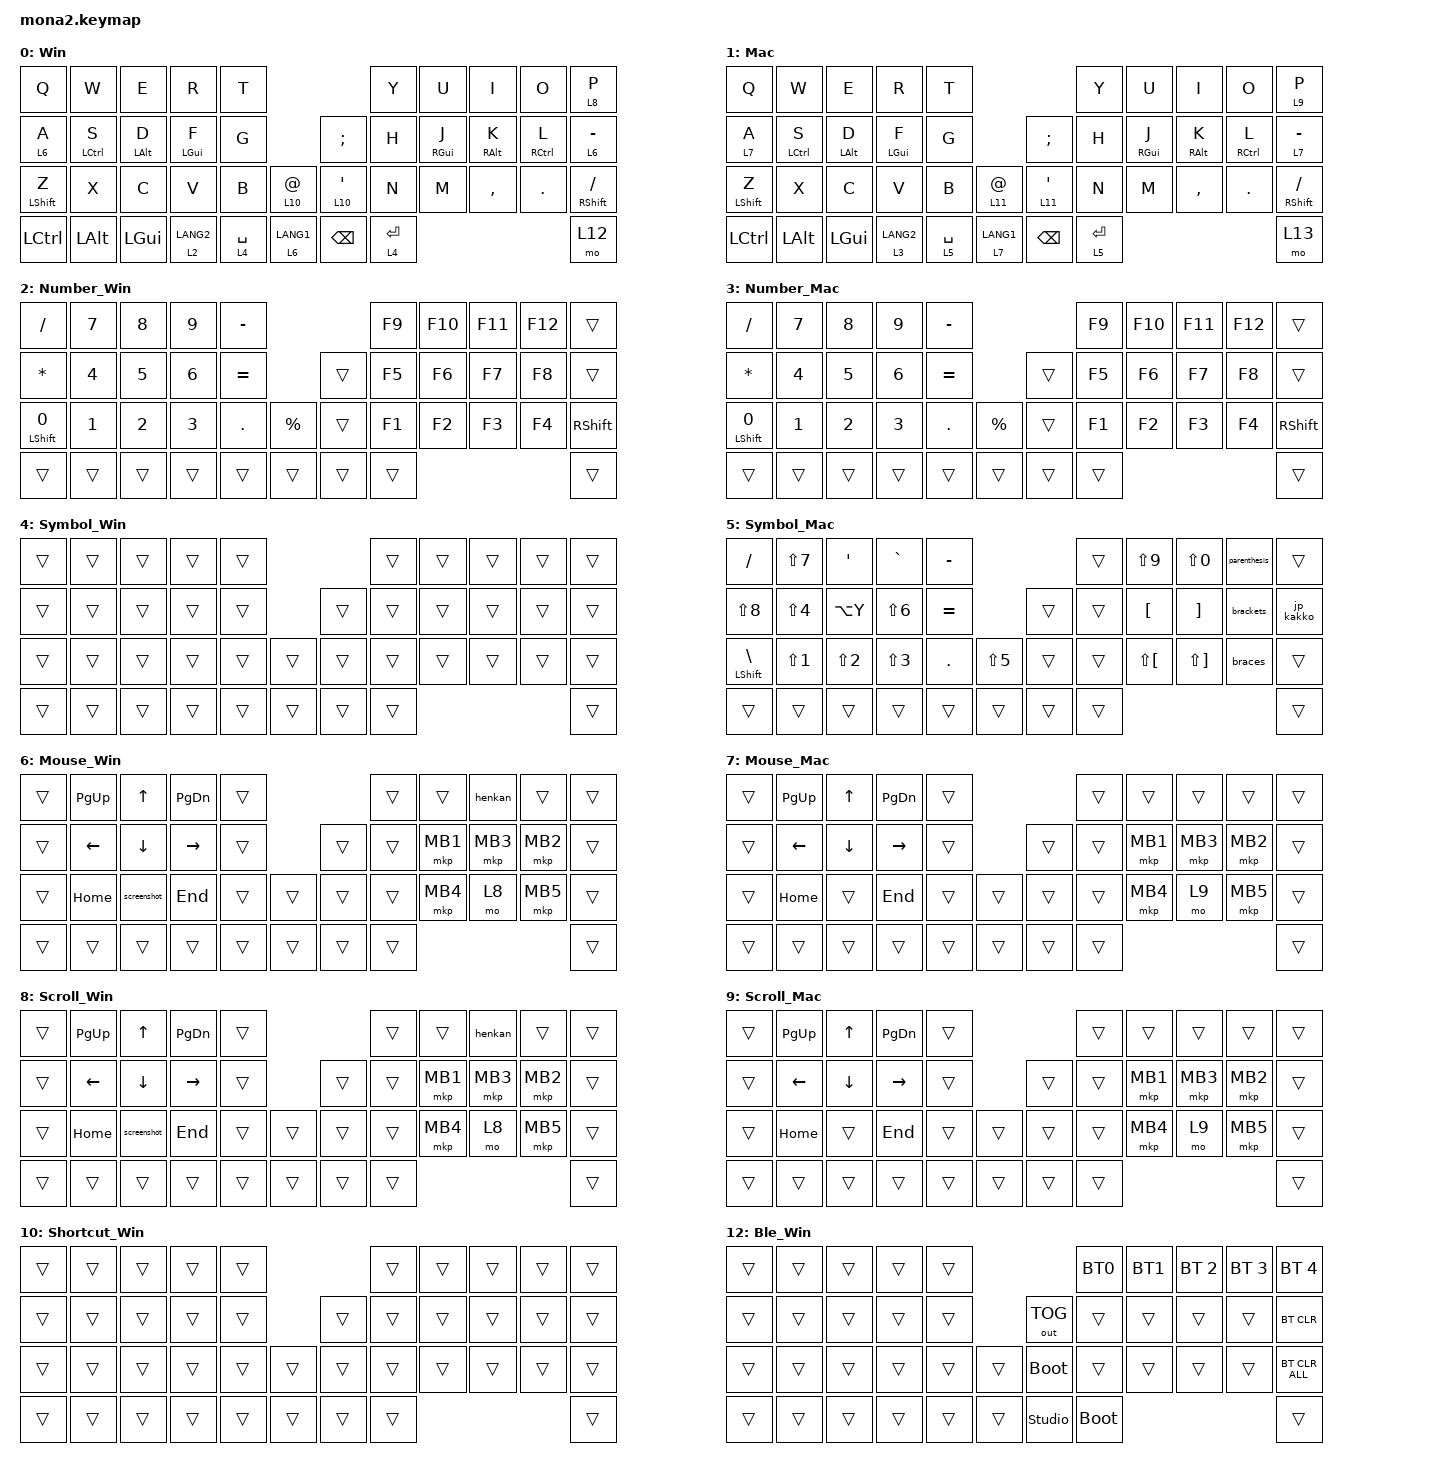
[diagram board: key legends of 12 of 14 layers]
#include <input/processors.dtsi>
#include <dt-bindings/zmk/input_transform.h>
#include <zephyr/dt-bindings/input/input-event-codes.h>
#include <behaviors/runtime-sensor-rotate.dtsi>
#include <behaviors.dtsi>
/* DYA Studio から作成したマクロを呼び出す `&rmacro <slot>` を定義する。
   slot は 0 〜 CONFIG_ZMK_RUNTIME_MACRO_COUNT-1 (現状 0〜7)。
   どのマクロがどのスロットに入っているかは DYA Studio のマクロ一覧で確認する。
   キーへの割り当ては DYA Studio のキーマップエディタからも行える。 */
#include <behaviors/runtime_macro.dtsi>
/* デフォルトレイヤー変更 behavior `&df`。
   DYA Studio の「OSごとのデフォルトレイヤー」から設定できるほか、
   キーマップエディタで `&df DF_SEL <layer>` / `&df DF_INC` を
   任意のキーに割り当てられる。 */
#include <behaviors/default_layer.dtsi>
#include <dt-bindings/zmk_behavior_default_layer/default_layer.h>
#include <dt-bindings/zmk/bt.h>
#include <dt-bindings/zmk/keys.h>
#include <dt-bindings/zmk/outputs.h>
#include <dt-bindings/zmk/pointing.h>
/* ZMK Layout Shift Module */
#include <layout_shift_kp_override.dtsi>

/* ZMK 側で 10 が定義済みなので警告回避のため一旦 undef */

#undef ZMK_POINTING_DEFAULT_SCRL_VAL

#define ZMK_POINTING_DEFAULT_SCRL_VAL 100

/ {
    behaviors {
        mg_set_0: behavior_mg_set_0 {
            compatible = "zmk,behavior-mg-set-fixed";
            #binding-cells = <0>;
            display-name = "Mouse Gesture Key 0";
        };

        mg_set_1: behavior_mg_set_1 {
            compatible = "zmk,behavior-mg-set-fixed";
            #binding-cells = <0>;
            display-name = "Mouse Gesture Key 1";
        };

        mg_set_2: behavior_mg_set_2 {
            compatible = "zmk,behavior-mg-set-fixed";
            #binding-cells = <0>;
            display-name = "Mouse Gesture Key 2";
        };
    };
};

&mt {
    flavor = "balanced";
    quick-tap-ms = <200>;
    require-prior-idle-ms = <150>;
};

&lt {
    quick-tap-ms = <200>;
    /*
    flavor = "tap-preferred";
    tapping-term-ms = <300>;
    */
    flavor = "balanced";
    require-prior-idle-ms = <150>;
};

&msc {
    delay-ms = <0>;
    time-to-max-speed-ms = <0>;
    acceleration-exponent = <0>;
};

&tog_ls { layout-maps = <&layout_shift_map_us_to_jis &layout_shift_map_swap_ctrl_cmd>; };
&tog_ls_on { layout-maps = <&layout_shift_map_us_to_jis &layout_shift_map_swap_ctrl_cmd>; };
&tog_ls_off { layout-maps = <&layout_shift_map_us_to_jis &layout_shift_map_swap_ctrl_cmd>; };

/ {
    /* ─────────────────────────────────────────────────────────────
       コンボ (DYA Studio から編集可能)

       旧 `combos { compatible = "zmk,combos"; }` はコンパイル時固定で
       DYA Studio から編集できないため、zmk-feature-runtime-combo の
       「コンパイル時デフォルト」ノードへ移行した。
       ここに書いた内容はフラッシュ直後から有効で、設定を消しても復活する。
       DYA Studio 側で編集するとそのスロットだけ上書きされ、
       Web UI の "Reset to Default" でここの値へ戻せる。

       スロット総数は CONFIG_ZMK_RUNTIME_COMBO_MAX_COMBOS (現状 16)。
       未使用スロット (2〜15) は DYA Studio から自由に追加できる。
       ────────────────────────────────────────────────────────── */
    runtime_combo_defaults {
        compatible = "cormoran,runtime-combo-defaults";

        esc {
            slot = <0>;
            display-name = "Esc";
            key-positions = <38 39>;
            bindings = <&kp ESC>;
        };

        tab {
            slot = <1>;
            display-name = "Tab";
            key-positions = <11 12>;
            bindings = <&kp TAB>;
        };

        toggle_us_jis {
            slot = <2>;
            display-name = "Toggle US<->JIS";
            key-positions = <4 5>;
            bindings = <&tog_ls>;
        };
    };

    /* 静的マクロ。キーマップ上で &BT0 / &screenshot などの名前で直接
       参照しているため、そのまま残している (DYA Studio 上では編集不可)。
       DYA Studio から編集したいマクロは Web UI で新規作成し、
       キーに `&rmacro <slot>` を割り当てて使う。 */
    macros {
        to_layer_0: to_layer_0 {
            compatible = "zmk,behavior-macro-one-param";
            #binding-cells = <1>;
            bindings = <&to 0 &macro_param_1to1 &kp MACRO_PLACEHOLDER>;
            label = "TO_LAYER_0";
        };

        BT0: BT0 {
            compatible = "zmk,behavior-macro";
            #binding-cells = <0>;
            bindings =
                <&tog_off 0 &tog_off 1>,
                <&macro_wait_time 200>,
                <&bt BT_SEL 0>,
                <&macro_wait_time 500>,
                <&tog_on 0>;

            label = "BT0";
        };

        BT1: BT1 {
            compatible = "zmk,behavior-macro";
            #binding-cells = <0>;
            bindings =
                <&tog_off 0 &tog_off 1>,
                <&macro_wait_time 200>,
                <&bt BT_SEL 1>,
                <&macro_wait_time 500>,
                <&tog_on 1>;

            label = "BT1";
        };

        screenshot: screenshot {
            compatible = "zmk,behavior-macro";
            #binding-cells = <0>;
            bindings =
                <&macro_press>,
                <&kp LEFT_GUI &kp RSHIFT>,
                <&macro_wait_time 20>,
                <&macro_tap>,
                <&kp S>,
                <&macro_release>,
                <&kp LEFT_GUI &kp RSHIFT>;

            label = "SCREENSHOT";
        };

        henkan: henkan {
            compatible = "zmk,behavior-macro";
            #binding-cells = <0>;
            bindings =
                <&macro_press>,
                <&kp LEFT_ALT>,
                <&macro_wait_time 20>,
                <&macro_tap>,
                <&kp GRAVE>,
                <&macro_release>,
                <&kp LEFT_ALT>;

            label = "HENKAN";
        };

        parenthesis: parenthesis {
            compatible = "zmk,behavior-macro";
            #binding-cells = <0>;
            bindings = 
                <&kp LANG2>,
                <&macro_wait_time 50>,
                <&kp LEFT_PARENTHESIS>,
                <&kp RIGHT_PARENTHESIS>,
                <&kp LEFT>;
        };

        brackets: brackets {
            compatible = "zmk,behavior-macro";
            #binding-cells = <0>;
            bindings = 
                <&kp LANG2>,
                <&macro_wait_time 50>,
                <&kp LEFT_BRACKET>,
                <&kp RIGHT_BRACKET>,
                <&kp LEFT>;
        };

        braces: braces {
            compatible = "zmk,behavior-macro";
            #binding-cells = <0>;
            bindings = 
                <&kp LANG2>,
                <&macro_wait_time 50>,
                <&kp LEFT_BRACE>,
                <&kp RIGHT_BRACE>,
                <&kp LEFT>;
        };

        jp_kakko: jp_kakko {
            compatible = "zmk,behavior-macro";
            #binding-cells = <0>;
            bindings = 
                <&kp LANG1>,
                <&macro_wait_time 50>,
                <&kp LEFT_BRACKET>,
                <&kp RIGHT_BRACKET>,
                <&kp ENTER>,
                <&kp LEFT>;
        };
    };

    behaviors {
        lt_to_layer_0: lt_to_layer_0 {
            compatible = "zmk,behavior-hold-tap";
            label = "LAYER_TAP_TO_0";
            bindings = <&mo>, <&to_layer_0>;

            #binding-cells = <2>;
            tapping-term-ms = <200>;
        };

        tp_repeat_mo1: tp_repeat_mo1 {
            compatible = "zmk,behavior-hold-tap";
            label = "TP_REPEAT_MO1";
            bindings = <&mo>, <&key_repeat>;

            #binding-cells = <2>;
            tapping-term-ms = <200>;
        };

        // エンコーダ用 runtime-configurable sensor rotate
        // デフォルトはスクロール (cw=SCRL_DOWN, ccw=SCRL_UP)
        // DYA Studio Web UI から レイヤーごとに cw/ccw の binding を
        // kp C_VOL_UP/DN や kp LEFT/RIGHT などへ動的変更可能

        rsr_scrl_up_down: rsr_scrl_up_down {
            compatible = "zmk,behavior-runtime-sensor-rotate";
            #sensor-binding-cells = <0>;
            tap-ms = <16>;
            cw-binding = <&msc SCRL_DOWN>;
            ccw-binding = <&msc SCRL_UP>;
        };

        rsr_scrl_right_left: rsr_scrl_right_left {
            compatible = "zmk,behavior-runtime-sensor-rotate";
            #sensor-binding-cells = <0>;
            tap-ms = <16>;
            cw-binding = <&msc SCRL_LEFT>;
            ccw-binding = <&msc SCRL_RIGHT>;
        };

        /*
        rsr_mouse_scroll: mouse_wheel_scroll {
            compatible = "zmk,behavior-sensor-rotate-var";
            #sensor-binding-cells = <2>;
            bindings = <&msc>, <&msc>;
            // 追加: スクロールのタップ時間を設定 (20ms)
            tap-ms = <20>;
        };
        */

        tog_on: toggle_layer_on_only {
            compatible = "zmk,behavior-toggle-layer";
            #binding-cells = <1>;
            display-name = "Toggle Layer On";
            toggle-mode = "on";
        };

        tog_off: toggle_layer_off_only {
            compatible = "zmk,behavior-toggle-layer";
            #binding-cells = <1>;
            display-name = "Toggle Layer Off";
            toggle-mode = "off";
        };

        zfold: zfold {
            compatible = "zmk,behavior-hold-tap";
            label = "ZFOLD";
            bindings = <&kp>, <&kp>;

            #binding-cells = <2>;
            tapping-term-ms = <300>;
            flavor = "hold-preferred";
            quick-tap-ms = <150>;
            hold-while-undecided;
        };

        zfoldZ: zfoldZ {
            compatible = "zmk,behavior-tap-dance";
            label = "ZFOLDZ";
            #binding-cells = <0>;
            bindings = <&zfold LEFT_SHIFT Z>, <&kp LS(Z)>;
        };
    };

    /* Defined Keymap Layers
        0   :   Win
        1   :   Mac
        2   :   Number_Win
        3   :   Number_Mac
        4   :   Symbol_Win
        5   :   Symbol_Mac
        6   :   Mouse_Win
        7   :   Mouse_Mac
        8   :   Scroll_Win
        9   :   Scroll_Mac
        10  :   Shortcut_Win
        11  :   Shortcut_Mac
        12  :   Ble_Win
        13  :   Ble_Mac
    */
    /* moNa2 Physical Key Layout
        bindings = <
            K0      K1      K2      K3      K4                          K5      K6      K7      K8      K9
            K10     K11     K12     K13     K14                 K15     K16     K17     K18     K19     K20
            K21     K22     K23     K24     K25     K26         K27     K28     K29     K30     K31     K32
            K33     K34     K35     K36     K37     K38         K39     K40                             K41
        >;
    */
    keymap {
        compatible = "zmk,keymap";

        win_layer {
            display-name = "Win";
            bindings = <
&kp Q             &kp W         &kp E         &kp R        &kp T                                       &kp Y          &kp U      &kp I      &kp O        &lt 8 P
&lt 6 A           &mt LCTRL S   &mt LALT D    &mt LGUI F   &kp G                        &kp SEMICOLON  &kp H          &mt RGUI J &mt RALT K &mt RCTRL L  &lt 6 MINUS
&mt LSHFT Z       &kp X         &kp C         &kp V        &kp B        &lt 10 AT       &lt 10 SQT     &kp N          &kp M      &kp COMMA  &kp DOT      &mt RSHFT SLASH
&kp LCTRL         &kp LALT      &kp LGUI      &lt 2 LANG2  &lt 4 SPACE  &lt 6 LANG1     &kp BSPC       &lt 4 ENTER                                       &mo 12
            >;

            sensor-bindings = <&rsr_scrl_up_down>, <&inc_dec_kp C_VOL_DN C_VOL_UP>;
        };

        mac_layer {
            display-name = "Mac";
            bindings = <
&kp Q             &kp W         &kp E         &kp R        &kp T                                       &kp Y          &kp U      &kp I      &kp O        &lt 9 P
&lt 7 A           &mt LCTRL S   &mt LALT D    &mt LGUI F   &kp G                        &kp SEMICOLON  &kp H          &mt RGUI J &mt RALT K &mt RCTRL L  &lt 7 MINUS
&mt LSHFT Z       &kp X         &kp C         &kp V        &kp B        &lt 11 AT       &lt 11 SQT     &kp N          &kp M      &kp COMMA  &kp DOT      &mt RSHFT SLASH
&kp LCTRL         &kp LALT      &kp LGUI      &lt 3 LANG2  &lt 5 SPACE  &lt 7 LANG1     &kp BSPC       &lt 5 ENTER                                       &mo 13
            >;

            sensor-bindings = <&rsr_scrl_up_down>, <&inc_dec_kp C_VOL_DN C_VOL_UP>;
        };

        num_win {
            display-name = "Number_Win";
            bindings = <
&kp SLASH       &kp N7 &kp N8 &kp N9 &kp MINUS                       &kp F9   &kp F10 &kp F11 &kp F12 &trans
&kp ASTERISK    &kp N4 &kp N5 &kp N6 &kp EQUAL                &trans &kp F5   &kp F6  &kp F7  &kp F8  &trans
&mt LSHFT N0    &kp N1 &kp N2 &kp N3 &kp DOT   &kp PERCENT    &trans &kp F1   &kp F2  &kp F3  &kp F4  &kp RSHFT
&trans          &trans &trans &trans &trans    &trans         &trans &trans                           &trans
            >;

            sensor-bindings = <&rsr_scrl_up_down>;
        };

        num_mac {
            display-name = "Number_Mac";
            bindings = <
&kp SLASH       &kp N7 &kp N8 &kp N9 &kp MINUS                       &kp F9   &kp F10 &kp F11 &kp F12 &trans
&kp ASTERISK    &kp N4 &kp N5 &kp N6 &kp EQUAL                &trans &kp F5   &kp F6  &kp F7  &kp F8  &trans
&mt LSHFT N0    &kp N1 &kp N2 &kp N3 &kp DOT   &kp PERCENT    &trans &kp F1   &kp F2  &kp F3  &kp F4  &kp RSHFT
&trans          &trans &trans &trans &trans    &trans         &trans &trans                           &trans
            >;

            sensor-bindings = <&rsr_scrl_up_down>;
        };

        symbol_win {
            display-name = "Symbol_Win";
            bindings = <
&trans  &trans  &trans  &trans  &trans                    &trans  &trans  &trans  &trans  &trans
&trans  &trans  &trans  &trans  &trans            &trans  &trans  &trans  &trans  &trans  &trans
&trans  &trans  &trans  &trans  &trans  &trans    &trans  &trans  &trans  &trans  &trans  &trans
&trans  &trans  &trans  &trans  &trans  &trans    &trans  &trans                          &trans
            >;

            sensor-bindings = <&rsr_scrl_up_down>;
        };

        symbol_mac {
            display-name = "Symbol_Mac";
            bindings = <
&kp SLASH       &kp LS(N7)  &kp SQT     &kp GRAVE   &kp MINUS                       &trans  &kp LS(N9)      &kp LS(N0)      &parenthesis    &trans
&kp LS(N8)      &kp LS(N4)  &kp LA(Y)   &kp LS(N6)  &kp EQUAL               &trans  &trans  &kp LBKT        &kp RBKT        &brackets       &jp_kakko
&mt LSHFT BSLH  &kp LS(N1)  &kp LS(N2)  &kp LS(N3)  &kp DOT     &kp LS(N5)  &trans  &trans  &kp LS(LBKT)    &kp LS(RBKT)    &braces         &trans
&trans          &trans      &trans      &trans      &trans      &trans      &trans  &trans                                                  &trans
            >;

            sensor-bindings = <&rsr_scrl_up_down>;
        };

        mouse_win {
            display-name = "Mouse_Win";
            bindings = <
&trans  &kp PG_UP       &kp UP          &kp PG_DN        &trans                             &trans      &trans          &henkan         &trans          &trans
&trans  &kp LEFT        &kp DOWN        &kp RIGHT        &trans                 &trans      &trans      &mkp MB1        &mkp MB3        &mkp MB2        &trans
&trans  &kp HOME        &screenshot     &kp END          &trans     &trans      &trans      &trans      &mkp MB4        &mo 8           &mkp MB5        &trans
&trans  &trans          &trans          &trans           &trans     &trans      &trans      &trans                                                      &trans
            >;

            sensor-bindings = <&rsr_scrl_up_down>;
        };

        mouse_mac {
            display-name = "Mouse_Mac";
            bindings = <
&trans  &kp PG_UP   &kp UP    &kp PG_DN     &trans                             &trans      &trans          &trans          &trans          &trans
&trans  &kp LEFT    &kp DOWN  &kp RIGHT     &trans                 &trans      &trans      &mkp MB1        &mkp MB3        &mkp MB2        &trans
&trans  &kp HOME    &trans    &kp END       &trans     &trans      &trans      &trans      &mkp MB4        &mo 9           &mkp MB5        &trans
&trans  &trans      &trans    &trans        &trans     &trans      &trans      &trans                                                      &trans
            >;

            sensor-bindings = <&rsr_scrl_up_down>;
        };

        scroll_win {
            display-name = "Scroll_Win";
            bindings = <
&trans  &kp PG_UP   &kp UP          &kp PG_DN   &trans                             &trans      &trans          &henkan         &trans          &trans
&trans  &kp LEFT    &kp DOWN        &kp RIGHT   &trans                 &trans      &trans      &mkp MB1        &mkp MB3        &mkp MB2        &trans
&trans  &kp HOME    &screenshot     &kp END     &trans     &trans      &trans      &trans      &mkp MB4        &mo 8           &mkp MB5        &trans
&trans  &trans      &trans          &trans      &trans     &trans      &trans      &trans                                                      &trans
            >;

            sensor-bindings = <&rsr_scrl_right_left>;
        };

        scroll_mac {
            display-name = "Scroll_Mac";
            bindings = <
&trans  &kp PG_UP   &kp UP      &kp PG_DN   &trans                             &trans      &trans          &trans          &trans          &trans
&trans  &kp LEFT    &kp DOWN    &kp RIGHT   &trans                 &trans      &trans      &mkp MB1        &mkp MB3        &mkp MB2        &trans
&trans  &kp HOME    &trans      &kp END     &trans     &trans      &trans      &trans      &mkp MB4        &mo 9           &mkp MB5        &trans
&trans  &trans      &trans      &trans      &trans     &trans      &trans      &trans                                                      &trans
            >;

            sensor-bindings = <&rsr_scrl_right_left>;
        };

        shortcut_win {
            display-name = "Shortcut_Win";
            bindings = <
&trans  &trans  &trans  &trans  &trans                    &trans  &trans    &trans    &trans    &trans
&trans  &trans  &trans  &trans  &trans            &trans  &trans  &trans    &trans    &trans    &trans
&trans  &trans  &trans  &trans  &trans  &trans    &trans  &trans  &trans    &trans    &trans    &trans
&trans  &trans  &trans  &trans  &trans  &trans    &trans  &trans                                &trans
            >;

            sensor-bindings = <&rsr_scrl_up_down>;
        };

        shortcut_mac {
            display-name = "Shortcut_Mac";
            bindings = <
&trans  &trans              &kp LA(LG(UP))      &trans              &trans                        &kp LC(LA(BSPC))          &kp LC(LA(U))       &kp LC(LA(UP))      &kp LC(LA(I))       &kp LC(LA(ENTER))
&trans  &kp LA(LG(LEFT))    &kp LA(LG(DOWN))    &kp LA(LG(RIGHT))   &trans                &trans  &kp LC(LA(LG(LEFT)))      &kp LC(LA(LEFT))    &kp LC(LA(C))       &kp LC(LA(RIGHT))   &kp LC(LA(LG(RIGHT)))
&trans  &trans              &trans              &trans              &trans      &trans    &trans  &kp LC(LS(LA(LG(LEFT))))  &kp LC(LA(J))       &kp LC(LA(DOWN))    &kp LC(LA(K))       &kp LC(LS(LA(LG(RIGHT))))
&trans  &trans              &trans              &trans              &trans      &trans    &trans  &trans                                                                                &trans
            >;

            sensor-bindings = <&rsr_scrl_up_down>;
        };

        ble_win {
            display-name = "Ble_Win";
            bindings = <
&trans  &trans  &trans  &trans  &trans                              &BT0         &BT1    &bt BT_SEL 2  &bt BT_SEL 3  &bt BT_SEL 4
&trans  &trans  &trans  &trans  &trans            &out OUT_TOG      &trans       &trans  &trans        &trans        &bt BT_CLR
&trans  &trans  &trans  &trans  &trans  &trans    &bootloader       &trans       &trans  &trans        &trans        &bt BT_CLR_ALL
&trans  &trans  &trans  &trans  &trans  &trans    &studio_unlock    &bootloader                                      &trans
            >;
        };

        ble_mac {
            display-name = "Ble_Mac";
            bindings = <
&trans  &trans  &trans  &trans  &trans                              &BT0         &BT1    &bt BT_SEL 2  &bt BT_SEL 3  &bt BT_SEL 4
&trans  &trans  &trans  &trans  &trans            &out OUT_TOG      &trans       &trans  &trans        &trans        &bt BT_CLR
&trans  &trans  &trans  &trans  &trans  &trans    &bootloader       &trans       &trans  &trans        &trans        &bt BT_CLR_ALL
&trans  &trans  &trans  &trans  &trans  &trans    &studio_unlock    &bootloader                                      &trans
            >;
        };
    };
};
